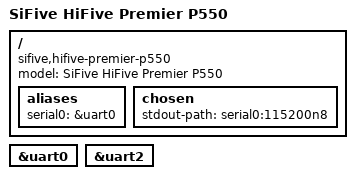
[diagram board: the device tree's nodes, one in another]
// SPDX-License-Identifier: (GPL-2.0 OR MIT)
/*
 * Copyright (c) 2024, Beijing ESWIN Computing Technology Co., Ltd.
 */

/dts-v1/;

#include "eic7700.dtsi"

/ {
	compatible = "sifive,hifive-premier-p550", "eswin,eic7700";
	model = "SiFive HiFive Premier P550";

	aliases {
		serial0 = &uart0;
	};

	chosen {
		stdout-path = "serial0:115200n8";
	};
};

&uart0 {
	status = "okay";
};

&uart2 {
	status = "okay";
};
